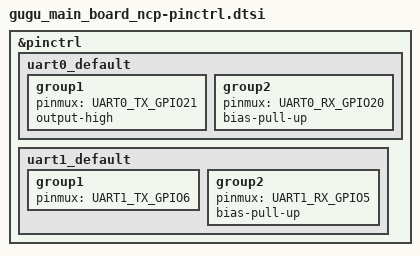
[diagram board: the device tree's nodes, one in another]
#include <zephyr/dt-bindings/pinctrl/esp-pinctrl-common.h>
#include <dt-bindings/pinctrl/esp32c3-pinctrl.h>
#include <zephyr/dt-bindings/pinctrl/esp32c3-gpio-sigmap.h>

&pinctrl {

	uart0_default: uart0_default {
		group1 {
			pinmux = <UART0_TX_GPIO21>;
			output-high;
		};
		group2 {
			pinmux = <UART0_RX_GPIO20>;
			bias-pull-up;
		};
	};

	uart1_default: uart1_default {
		group1 {
			pinmux = <UART1_TX_GPIO6>;
		};
		group2 {
			pinmux = <UART1_RX_GPIO5>;
			bias-pull-up;
		};
	};
};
